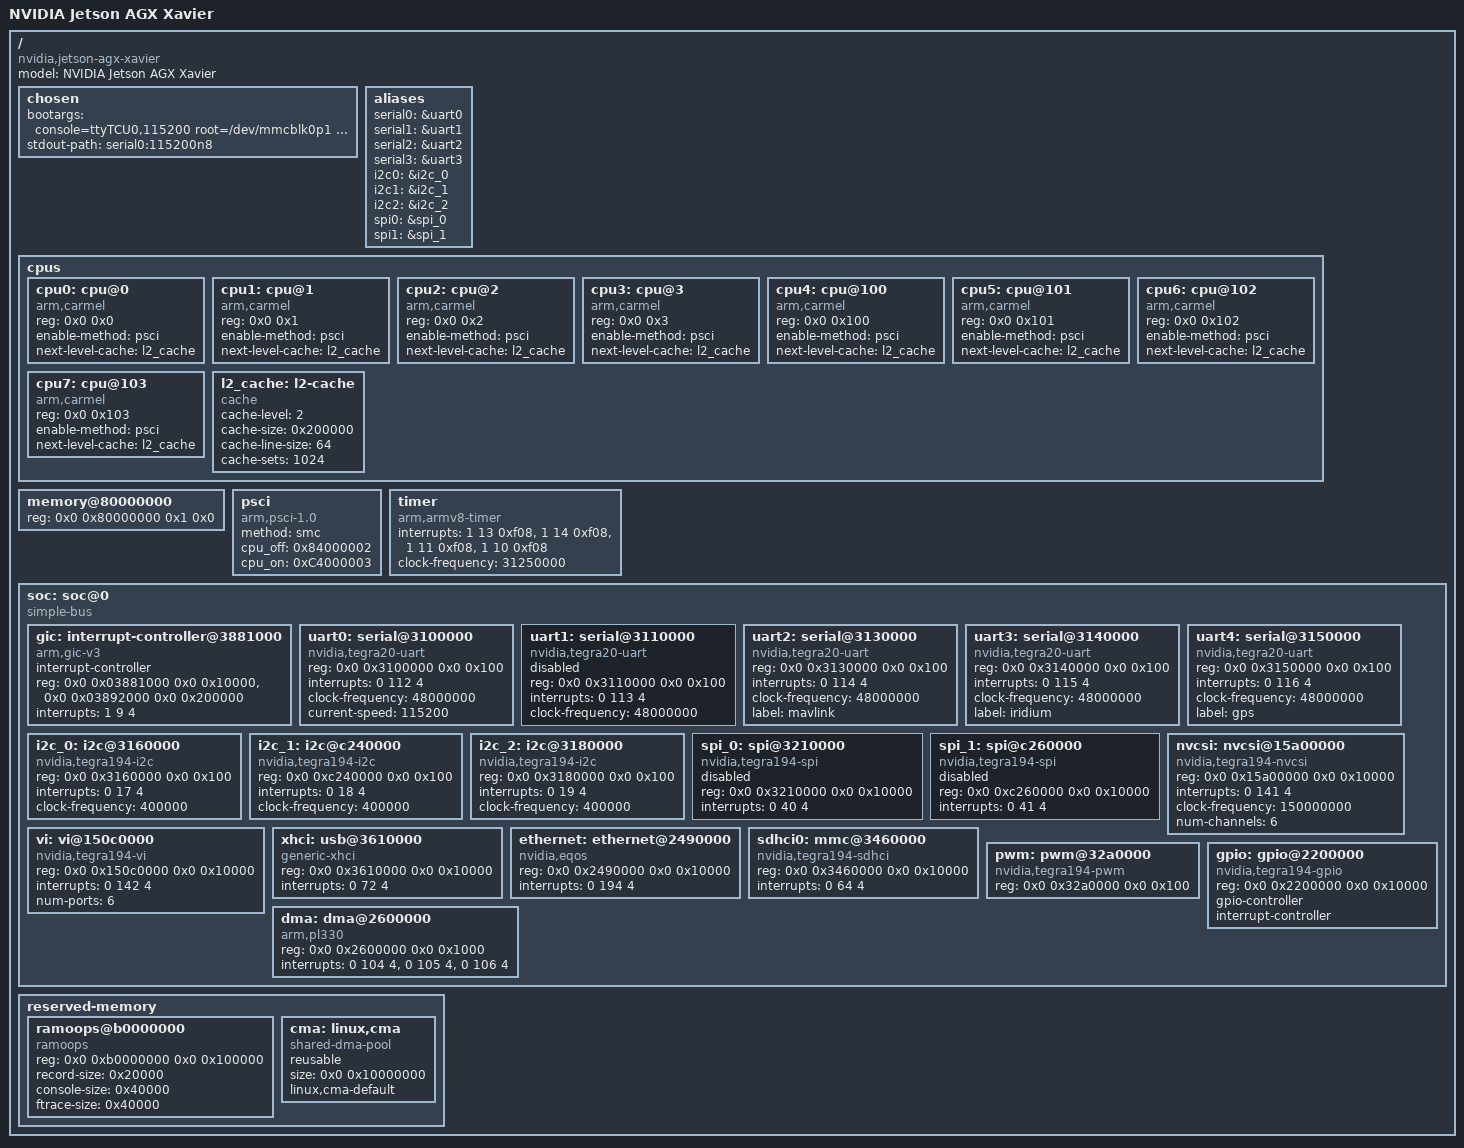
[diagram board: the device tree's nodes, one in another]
/dts-v1/;

/ {
    model = "NVIDIA Jetson AGX Xavier";
    compatible = "nvidia,jetson-agx-xavier", "nvidia,tegra194";
    #address-cells = <2>;
    #size-cells = <2>;

    chosen {
        bootargs = "console=ttyTCU0,115200 root=/dev/mmcblk0p1 rw rootwait";
        stdout-path = "serial0:115200n8";
    };

    aliases {
        serial0 = &uart0;
        serial1 = &uart1;
        serial2 = &uart2;
        serial3 = &uart3;
        i2c0 = &i2c_0;
        i2c1 = &i2c_1;
        i2c2 = &i2c_2;
        spi0 = &spi_0;
        spi1 = &spi_1;
    };

    cpus {
        #address-cells = <2>;
        #size-cells = <0>;

        cpu0: cpu@0 {
            device_type = "cpu";
            compatible = "arm,carmel";
            reg = <0x0 0x0>;
            enable-method = "psci";
            next-level-cache = <&l2_cache>;
        };

        cpu1: cpu@1 {
            device_type = "cpu";
            compatible = "arm,carmel";
            reg = <0x0 0x1>;
            enable-method = "psci";
            next-level-cache = <&l2_cache>;
        };

        cpu2: cpu@2 {
            device_type = "cpu";
            compatible = "arm,carmel";
            reg = <0x0 0x2>;
            enable-method = "psci";
            next-level-cache = <&l2_cache>;
        };

        cpu3: cpu@3 {
            device_type = "cpu";
            compatible = "arm,carmel";
            reg = <0x0 0x3>;
            enable-method = "psci";
            next-level-cache = <&l2_cache>;
        };

        cpu4: cpu@100 {
            device_type = "cpu";
            compatible = "arm,carmel";
            reg = <0x0 0x100>;
            enable-method = "psci";
            next-level-cache = <&l2_cache>;
        };

        cpu5: cpu@101 {
            device_type = "cpu";
            compatible = "arm,carmel";
            reg = <0x0 0x101>;
            enable-method = "psci";
            next-level-cache = <&l2_cache>;
        };

        cpu6: cpu@102 {
            device_type = "cpu";
            compatible = "arm,carmel";
            reg = <0x0 0x102>;
            enable-method = "psci";
            next-level-cache = <&l2_cache>;
        };

        cpu7: cpu@103 {
            device_type = "cpu";
            compatible = "arm,carmel";
            reg = <0x0 0x103>;
            enable-method = "psci";
            next-level-cache = <&l2_cache>;
        };

        l2_cache: l2-cache {
            compatible = "cache";
            cache-level = <2>;
            cache-size = <0x200000>;
            cache-line-size = <64>;
            cache-sets = <1024>;
        };
    };

    memory@80000000 {
        device_type = "memory";
        reg = <0x0 0x80000000 0x1 0x0>;
    };

    psci {
        compatible = "arm,psci-1.0";
        method = "smc";
        cpu_off = <0x84000002>;
        cpu_on = <0xC4000003>;
    };

    timer {
        compatible = "arm,armv8-timer";
        interrupts = <1 13 0xf08>,
                     <1 14 0xf08>,
                     <1 11 0xf08>,
                     <1 10 0xf08>;
        clock-frequency = <31250000>;
    };

    soc: soc@0 {
        compatible = "simple-bus";
        #address-cells = <2>;
        #size-cells = <2>;
        ranges;

        gic: interrupt-controller@3881000 {
            compatible = "arm,gic-v3";
            #interrupt-cells = <3>;
            interrupt-controller;
            reg = <0x0 0x03881000 0x0 0x10000>,
                  <0x0 0x03892000 0x0 0x200000>;
            interrupts = <1 9 4>;
        };

        uart0: serial@3100000 {
            compatible = "nvidia,tegra20-uart";
            reg = <0x0 0x3100000 0x0 0x100>;
            interrupts = <0 112 4>;
            clock-frequency = <48000000>;
            current-speed = <115200>;
            status = "okay";
        };

        uart1: serial@3110000 {
            compatible = "nvidia,tegra20-uart";
            reg = <0x0 0x3110000 0x0 0x100>;
            interrupts = <0 113 4>;
            clock-frequency = <48000000>;
            status = "disabled";
        };

        uart2: serial@3130000 {
            compatible = "nvidia,tegra20-uart";
            reg = <0x0 0x3130000 0x0 0x100>;
            interrupts = <0 114 4>;
            clock-frequency = <48000000>;
            status = "okay";
            label = "mavlink";
        };

        uart3: serial@3140000 {
            compatible = "nvidia,tegra20-uart";
            reg = <0x0 0x3140000 0x0 0x100>;
            interrupts = <0 115 4>;
            clock-frequency = <48000000>;
            status = "okay";
            label = "iridium";
        };

        uart4: serial@3150000 {
            compatible = "nvidia,tegra20-uart";
            reg = <0x0 0x3150000 0x0 0x100>;
            interrupts = <0 116 4>;
            clock-frequency = <48000000>;
            status = "okay";
            label = "gps";
        };

        i2c_0: i2c@3160000 {
            compatible = "nvidia,tegra194-i2c";
            reg = <0x0 0x3160000 0x0 0x100>;
            interrupts = <0 17 4>;
            clock-frequency = <400000>;
            status = "okay";
        };

        i2c_1: i2c@c240000 {
            compatible = "nvidia,tegra194-i2c";
            reg = <0x0 0xc240000 0x0 0x100>;
            interrupts = <0 18 4>;
            clock-frequency = <400000>;
            status = "okay";
        };

        i2c_2: i2c@3180000 {
            compatible = "nvidia,tegra194-i2c";
            reg = <0x0 0x3180000 0x0 0x100>;
            interrupts = <0 19 4>;
            clock-frequency = <400000>;
            status = "okay";
        };

        spi_0: spi@3210000 {
            compatible = "nvidia,tegra194-spi";
            reg = <0x0 0x3210000 0x0 0x10000>;
            interrupts = <0 40 4>;
            #address-cells = <1>;
            #size-cells = <0>;
            status = "disabled";
        };

        spi_1: spi@c260000 {
            compatible = "nvidia,tegra194-spi";
            reg = <0x0 0xc260000 0x0 0x10000>;
            interrupts = <0 41 4>;
            #address-cells = <1>;
            #size-cells = <0>;
            status = "disabled";
        };

        nvcsi: nvcsi@15a00000 {
            compatible = "nvidia,tegra194-nvcsi";
            reg = <0x0 0x15a00000 0x0 0x10000>;
            interrupts = <0 141 4>;
            clock-frequency = <150000000>;
            num-channels = <6>;
            status = "okay";
        };

        vi: vi@150c0000 {
            compatible = "nvidia,tegra194-vi";
            reg = <0x0 0x150c0000 0x0 0x10000>;
            interrupts = <0 142 4>;
            num-ports = <6>;
            status = "okay";
        };

        xhci: usb@3610000 {
            compatible = "generic-xhci";
            reg = <0x0 0x3610000 0x0 0x10000>;
            interrupts = <0 72 4>;
            status = "okay";
        };

        ethernet: ethernet@2490000 {
            compatible = "nvidia,eqos";
            reg = <0x0 0x2490000 0x0 0x10000>;
            interrupts = <0 194 4>;
            status = "okay";
        };

        sdhci0: mmc@3460000 {
            compatible = "nvidia,tegra194-sdhci";
            reg = <0x0 0x3460000 0x0 0x10000>;
            interrupts = <0 64 4>;
            status = "okay";
        };

        pwm: pwm@32a0000 {
            compatible = "nvidia,tegra194-pwm";
            reg = <0x0 0x32a0000 0x0 0x100>;
            #pwm-cells = <2>;
            status = "okay";
        };

        gpio: gpio@2200000 {
            compatible = "nvidia,tegra194-gpio";
            reg = <0x0 0x2200000 0x0 0x10000>;
            gpio-controller;
            #gpio-cells = <2>;
            interrupt-controller;
            #interrupt-cells = <2>;
            status = "okay";
        };

        dma: dma@2600000 {
            compatible = "arm,pl330";
            reg = <0x0 0x2600000 0x0 0x1000>;
            interrupts = <0 104 4>, <0 105 4>, <0 106 4>;
            #dma-cells = <1>;
            status = "okay";
        };
    };

    reserved-memory {
        #address-cells = <2>;
        #size-cells = <2>;
        ranges;

        ramoops@b0000000 {
            compatible = "ramoops";
            reg = <0x0 0xb0000000 0x0 0x100000>;
            record-size = <0x20000>;
            console-size = <0x40000>;
            ftrace-size = <0x40000>;
        };

        cma: linux,cma {
            compatible = "shared-dma-pool";
            reusable;
            size = <0x0 0x10000000>;
            linux,cma-default;
        };
    };
};
